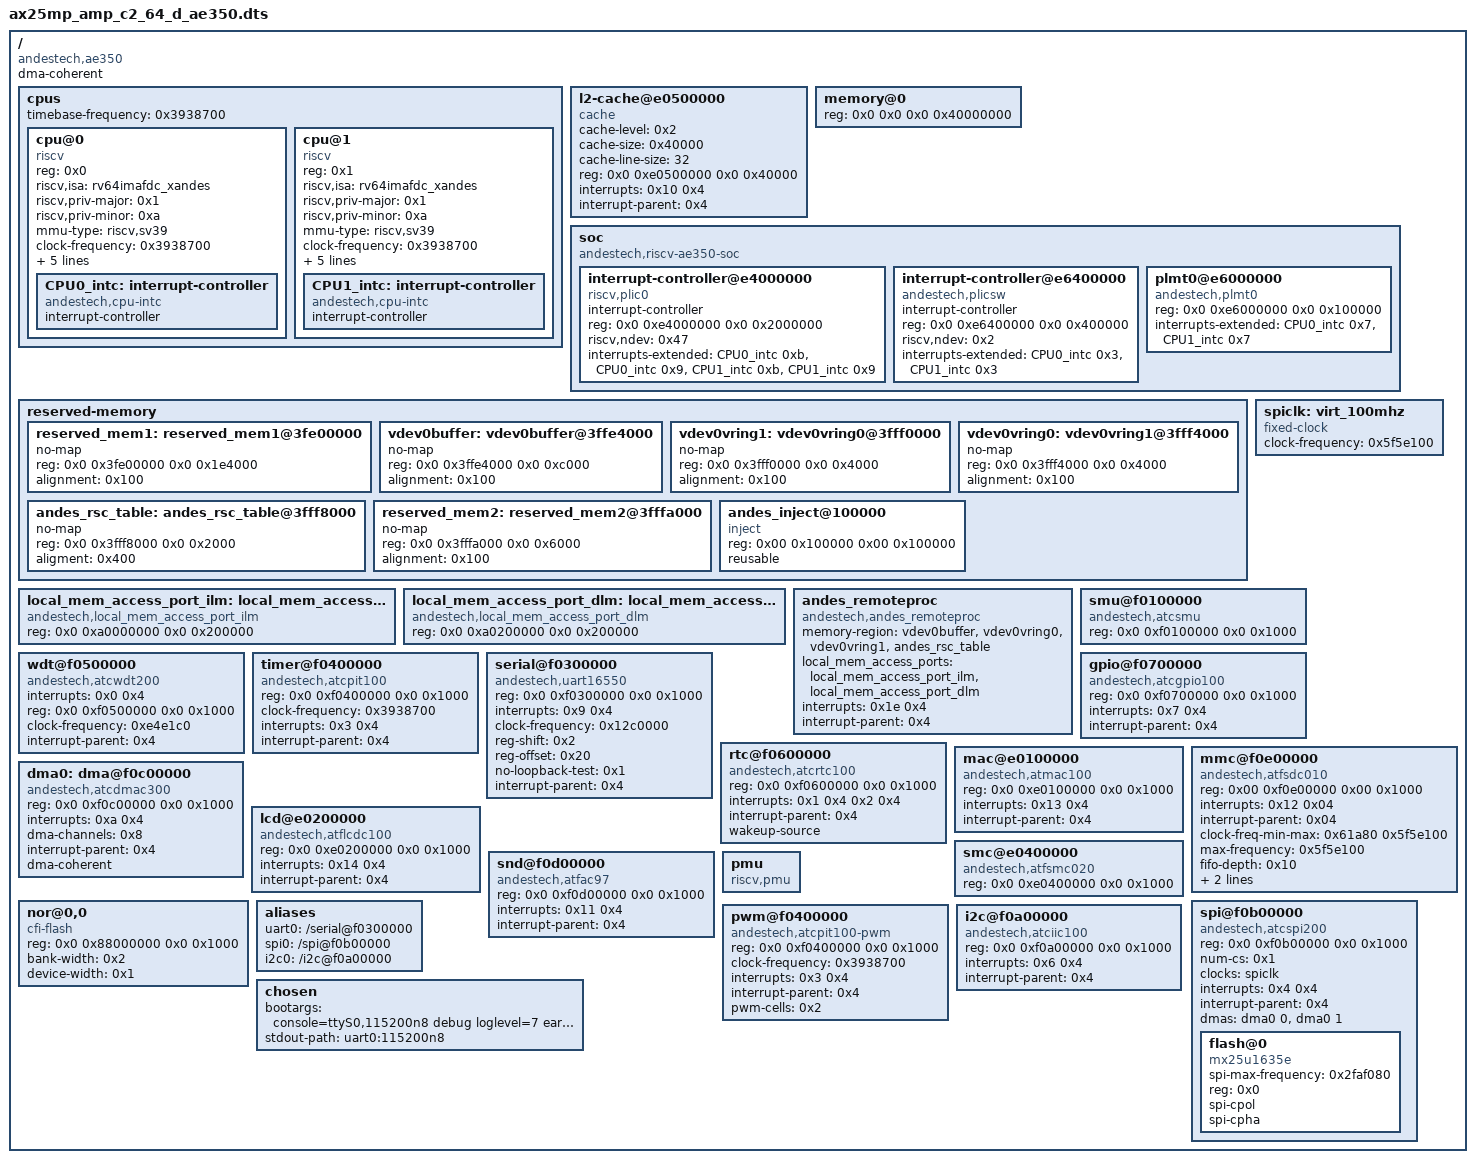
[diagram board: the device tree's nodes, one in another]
/dts-v1/;

/ {
	compatible = "andestech,ae350";
	#address-cells = <0x2>;
	#size-cells = <0x2>;
	dma-coherent;

	cpus {
		#address-cells = <0x1>;
		#size-cells = <0x0>;
		timebase-frequency = <0x3938700>;

		cpu@0 {
			device_type = "cpu";
			reg = <0x0>;
			status = "okay";
			compatible = "riscv";
			riscv,isa = "rv64imafdc_xandes";
			riscv,priv-major = <0x1>;
			riscv,priv-minor = <0xa>;
			mmu-type = "riscv,sv39";
			clock-frequency = <0x3938700>;
			i-cache-size = <0x8000>;
			i-cache-line-size = <0x20>;
			d-cache-size = <0x8000>;
			d-cache-line-size = <0x20>;
			next-level-cache = <0x1>;

			CPU0_intc: interrupt-controller {
				#interrupt-cells = <0x1>;
				interrupt-controller;
				compatible = "andestech,cpu-intc", "riscv,cpu-intc";
			};
		};
		cpu@1 {
			device_type = "cpu";
			reg = <0x1>;
			status = "okay";
			compatible = "riscv";
			riscv,isa = "rv64imafdc_xandes";
			riscv,priv-major = <0x1>;
			riscv,priv-minor = <0xa>;
			mmu-type = "riscv,sv39";
			clock-frequency = <0x3938700>;
			i-cache-size = <0x8000>;
			i-cache-line-size = <0x20>;
			d-cache-size = <0x8000>;
			d-cache-line-size = <0x20>;
			next-level-cache = <0x1>;

			CPU1_intc: interrupt-controller {
				#interrupt-cells = <0x1>;
				interrupt-controller;
				compatible = "andestech,cpu-intc", "riscv,cpu-intc";
			};
		};
	};

	l2-cache@e0500000 {
		compatible = "cache";
		cache-level = <0x2>;
		cache-size = <0x40000>;
		cache-line-size = <32>;
		reg = <0x0 0xe0500000 0x0 0x40000>;
		interrupts = <0x10 0x4>;
		interrupt-parent = <0x4>;
		phandle = <0x1>;
	};

	memory@0 {
		device_type = "memory";
		reg = <0x0 0x0 0x0 0x40000000>;
	};

	soc {
		#address-cells = <0x2>;
		#size-cells = <0x2>;
		compatible = "andestech,riscv-ae350-soc", "simple-bus";
		ranges;

		interrupt-controller@e4000000 {
			compatible = "riscv,plic0";
			#address-cells = <0x2>;
			#interrupt-cells = <0x2>;
			interrupt-controller;
			reg = <0x0 0xe4000000 0x0 0x2000000>;
			riscv,ndev = <0x47>;
			interrupts-extended = <&CPU0_intc 0xb &CPU0_intc 0x9 &CPU1_intc 0xb &CPU1_intc 0x9>;
			phandle = <0x4>;
		};

		interrupt-controller@e6400000 {
			compatible = "andestech,plicsw";
			#address-cells = <0x2>;
			#interrupt-cells = <0x2>;
			interrupt-controller;
			reg = <0x0 0xe6400000 0x0 0x400000>;
			riscv,ndev = <0x2>;
			interrupts-extended = <&CPU0_intc 0x3 &CPU1_intc 0x3>;
		};

		plmt0@e6000000 {
			compatible = "andestech,plmt0";
			reg = <0x0 0xe6000000 0x0 0x100000>;
			interrupts-extended = <&CPU0_intc 0x7 &CPU1_intc 0x7>;
		};
	};

	reserved-memory {
		#address-cells = <0x2>;
		#size-cells = <0x2>;
		ranges;

		reserved_mem1:reserved_mem1@3fe00000 {
			no-map;
			reg = <0x0 0x3fe00000 0x0 0x1e4000>;
			alignment = <0x100>;
		};

		vdev0buffer:vdev0buffer@3ffe4000 {
			no-map;
			reg = <0x0 0x3ffe4000 0x0 0xc000>;
			alignment = <0x100>;
		};
		vdev0vring1:vdev0vring0@3fff0000 {
			no-map;
			reg = <0x0 0x3fff0000 0x0 0x4000>;
			alignment = <0x100>;
		};
		vdev0vring0:vdev0vring1@3fff4000 {
			no-map;
			reg = <0x0 0x3fff4000 0x0 0x4000>;
			alignment = <0x100>;
		};

		andes_rsc_table:andes_rsc_table@3fff8000 {
			no-map;
			reg = <0x0 0x3fff8000 0x0 0x2000>;
			aligment = <0x400>;
		};

		reserved_mem2:reserved_mem2@3fffa000 {
			no-map;
			reg = <0x0 0x3fffa000 0x0 0x6000>;
			alignment = <0x100>;
		};

		andes_inject@100000 {
			compatible = "inject";
			reg = <0x00 0x100000 0x00 0x100000>;
			reusable;
		};
	};

	local_mem_access_port_ilm:local_mem_access_port_ilm@a0000000 {
		compatible = "andestech,local_mem_access_port_ilm";
		reg = <0x0 0xa0000000 0x0 0x200000>;
	};

	local_mem_access_port_dlm:local_mem_access_port_dlm@a0200000 {
		compatible = "andestech,local_mem_access_port_dlm";
		reg = <0x0 0xa0200000 0x0 0x200000>;
	};

	andes_remoteproc {
		compatible = "andestech,andes_remoteproc";
		memory-region = <&vdev0buffer>, <&vdev0vring0>,
				<&vdev0vring1>, <&andes_rsc_table>;
		local_mem_access_ports = <&local_mem_access_port_ilm>, <&local_mem_access_port_dlm>;
		interrupts = <0x1e 0x4>;
		interrupt-parent = <0x4>;
	};

	spiclk: virt_100mhz {
		#clock-cells = <0x0>;
		compatible = "fixed-clock";
		clock-frequency = <0x5f5e100>;
	};

	smu@f0100000 {
		compatible = "andestech,atcsmu";
		reg = <0x0 0xf0100000 0x0 0x1000>;
	};

	wdt@f0500000 {
		compatible = "andestech,atcwdt200";
		interrupts = <0x0 0x4>;
		reg = <0x0 0xf0500000 0x0 0x1000>;
		clock-frequency = <0xe4e1c0>;
		interrupt-parent = <0x4>;
	};

	timer@f0400000 {
		compatible = "andestech,atcpit100";
		reg = <0x0 0xf0400000 0x0 0x1000>;
		clock-frequency = <0x3938700>;
		interrupts = <0x3 0x4>;
		interrupt-parent = <0x4>;
	};

	serial@f0300000 {
		compatible = "andestech,uart16550", "ns16550a";
		reg = <0x0 0xf0300000 0x0 0x1000>;
		interrupts = <0x9 0x4>;
		clock-frequency = <0x12c0000>;
		reg-shift = <0x2>;
		reg-offset = <0x20>;
		no-loopback-test = <0x1>;
		interrupt-parent = <0x4>;
	};

	gpio@f0700000 {
		compatible = "andestech,atcgpio100";
		reg = <0x0 0xf0700000 0x0 0x1000>;
		interrupts = <0x7 0x4>;
		interrupt-parent = <0x4>;
	};

	rtc@f0600000 {
		compatible = "andestech,atcrtc100";
		reg = <0x0 0xf0600000 0x0 0x1000>;
		interrupts = <0x1 0x4 0x2 0x4>;
		interrupt-parent = <0x4>;
		wakeup-source;
	};

	mac@e0100000 {
		compatible = "andestech,atmac100";
		reg = <0x0 0xe0100000 0x0 0x1000>;
		interrupts = <0x13 0x4>;
		interrupt-parent = <0x4>;
	};

	mmc@f0e00000 {
		compatible = "andestech,atfsdc010";
		reg = <0x00 0xf0e00000 0x00 0x1000>;
		interrupts = <0x12 0x04>;
		interrupt-parent = <0x04>;
		clock-freq-min-max = <0x61a80 0x5f5e100>;
		max-frequency = <0x5f5e100>;
		fifo-depth = <0x10>;
		dma-names = "rxtx";
		dmas = <&dma0 0x09>;
		dma-coherent;
	};

	dma0: dma@f0c00000 {
		compatible = "andestech,atcdmac300";
		reg = <0x0 0xf0c00000 0x0 0x1000>;
		interrupts = <0xa 0x4>;
		dma-channels = <0x8>;
		interrupt-parent = <0x4>;
		#dma-cells = <0x01>;
		dma-coherent;
	};

	lcd@e0200000 {
		compatible = "andestech,atflcdc100";
		reg = <0x0 0xe0200000 0x0 0x1000>;
		interrupts = <0x14 0x4>;
		interrupt-parent = <0x4>;
	};

	smc@e0400000 {
		compatible = "andestech,atfsmc020";
		reg = <0x0 0xe0400000 0x0 0x1000>;
	};

	snd@f0d00000 {
		compatible = "andestech,atfac97";
		reg = <0x0 0xf0d00000 0x0 0x1000>;
		interrupts = <0x11 0x4>;
		interrupt-parent = <0x4>;
	};

	pmu {
		device_type = "pmu";
		compatible = "riscv,pmu";
	};

	nor@0,0 {
		compatible = "cfi-flash";
		reg = <0x0 0x88000000 0x0 0x1000>;
		bank-width = <0x2>;
		device-width = <0x1>;
	};

	spi@f0b00000 {
		compatible = "andestech,atcspi200";
		reg = <0x0 0xf0b00000 0x0 0x1000>;
		#address-cells = <0x1>;
		#size-cells = <0x0>;
		num-cs = <0x1>;
		clocks = <&spiclk>;
		interrupts = <0x4 0x4>;
		interrupt-parent = <0x4>;
		dmas = <&dma0 0>, <&dma0 1>;
		dma-names = "spi_tx", "spi_rx";

		flash@0 {
			compatible = "mx25u1635e", "jedec,spi-nor";
			spi-max-frequency = <0x2faf080>;
			reg = <0x0>;
			spi-cpol;
			spi-cpha;
		};
	};

	pwm@f0400000 {
		compatible = "andestech,atcpit100-pwm";
		reg = <0x0 0xf0400000 0x0 0x1000>;
		clock-frequency = <0x3938700>;
		interrupts = <0x3 0x4>;
		interrupt-parent = <0x4>;
		pwm-cells = <0x2>;
	};

	i2c@f0a00000 {
		compatible = "andestech,atciic100";
		reg = <0x0 0xf0a00000 0x0 0x1000>;
		interrupts = <0x6 0x4>;
		interrupt-parent = <0x4>;
	};

	aliases {
		uart0 = "/serial@f0300000";
		spi0 = "/spi@f0b00000";
		i2c0 = "/i2c@f0a00000";
	};

	chosen {
		bootargs = "console=ttyS0,115200n8 debug loglevel=7 earlycon=sbi";
		stdout-path = "uart0:115200n8";
	};
};
